# nrf54l09_enga_application register map
Vendor: Nordic Semiconductor; Series: nrf54l; File version: 1
CPU: CM33 r0p4, little endian, MPU, FPU, 3 interrupt priority bits, 270 interrupts, 4 SAU regions
Registers are 32-bit, read-write, reset 0x0 unless marked. A register's access mark holds for its fields unless they carry their own. Offsets are from the block's base; [hi:lo] are bit positions; lines under a group give offsets from that group; {n}, {i} and the like mark numbered series; 'fields as' and 'values as' point back to an identical list.

## GLOBAL_ECB00_NS — AES ECB Mode Encryption 0
Base 0x4004B000
Same registers: GLOBAL_ECB00_S 0x5004B000
0x00 TASKS_START wo — Start ECB block encrypt
  [0] TASKS_START
    1=Trigger task
0x04 TASKS_STOP wo — Abort a possible executing ECB operation
  [0] TASKS_STOP
    1=Trigger task
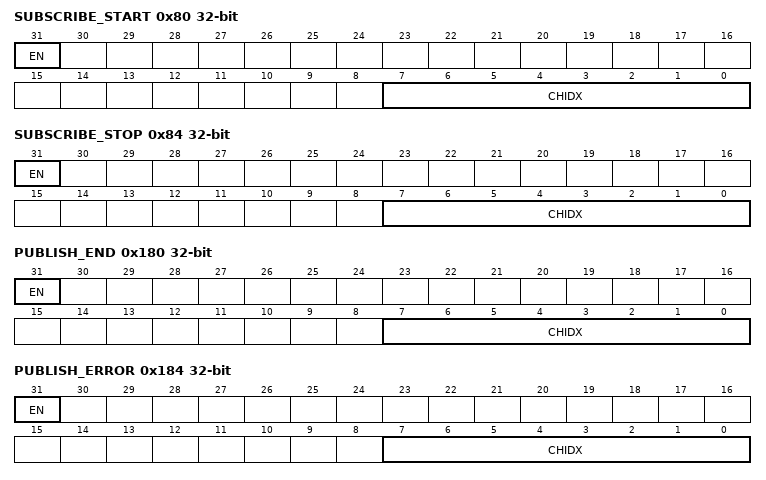
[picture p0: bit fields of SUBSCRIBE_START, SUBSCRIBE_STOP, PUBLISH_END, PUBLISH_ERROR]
0x80 SUBSCRIBE_START — Subscribe configuration for task START
  [31] EN
    0=Disabled (Disable subscription); 1=Enabled (Enable subscription)
  [7:0] CHIDX — DPPI channel that task START will subscribe to
0x84 SUBSCRIBE_STOP — Subscribe configuration for task STOP
  [31] EN
    values as SUBSCRIBE_START.EN
  [7:0] CHIDX — DPPI channel that task STOP will subscribe to
0x100 EVENTS_END — ECB block encrypt complete
  [0] EVENTS_END
    0=NotGenerated (Event not generated); 1=Generated (Event generated)
0x104 EVENTS_ERROR — ECB block encrypt aborted because of a STOP task or due to an error
  [0] EVENTS_ERROR
    values as EVENTS_END.EVENTS_END
0x180 PUBLISH_END — Publish configuration for event END
  [31] EN
    0=Disabled (Disable publishing); 1=Enabled (Enable publishing)
  [7:0] CHIDX — DPPI channel that event END will publish to
0x184 PUBLISH_ERROR — Publish configuration for event ERROR
  [31] EN
    values as PUBLISH_END.EN
  [7:0] CHIDX — DPPI channel that event ERROR will publish to
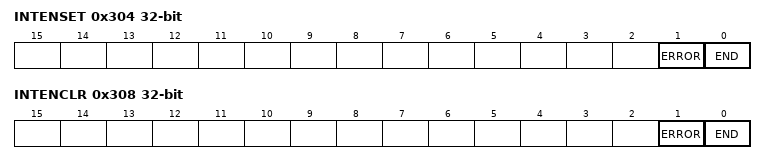
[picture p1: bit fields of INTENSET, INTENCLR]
0x304 INTENSET — Enable interrupt
  [1] ERROR — Write '1' to enable interrupt for event ERROR
    on read: 0=Disabled (Read: Disabled); 1=Enabled (Read: Enabled) | on write: 1=Set (Enable)
  [0] END — Write '1' to enable interrupt for event END
    values as ERROR
0x308 INTENCLR — Disable interrupt
  [1] ERROR — Write '1' to disable interrupt for event ERROR
    on read: 0=Disabled (Read: Disabled); 1=Enabled (Read: Enabled) | on write: 1=Clear (Disable)
  [0] END — Write '1' to disable interrupt for event END
    values as ERROR
0x400 ERRORSTATUS ro
  [2:0] ERRORSTATUS — Error status when the ERROR event is generated
    0=No errors have occurred; 1=PrematureInptrEnd (End of INPTR job list before data structure was read.); 2=PrematureOutptrEnd (End of OUTPTR job list before data structure was read.); 3=EncryptionTooSlow (Deprecated enumerator - Encryption aborted due to higher priority peripheral requesting or using the AES module.); 3=Aborted (Encryption aborted due to higher priority peripheral requesting or using the AES module.); 4=DmaError (Bus error during DMA access.)
0x510 KEY group — Unspecified
  {0x0+4j} VALUE[{j}] (j=0..3) wo — Description collection: 128-bit AES key
    [31:0] VALUE — AES 128-bit key value, bits (32*(n+1))-1 : (32*n)
0x530 IN group — IN EasyDMA channel
  0x00 PTR — Input pointer
    [31:0] PTR — Points to a job list containing unencrypted ECB data structure
0x538 OUT group — OUT EasyDMA channel
  0x00 PTR — Output pointer Points to a job list containing encrypted ECB data structure
    [31:0] PTR — Output pointer

## GLOBAL_GLITCHDET_S — Voltage glitch detectors
Base 0x5004E000
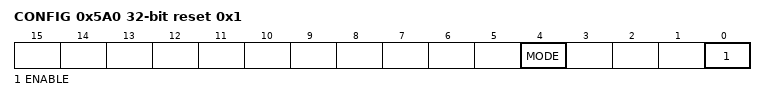
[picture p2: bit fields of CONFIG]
0x5A0 CONFIG reset 0x1 — Configuration for glitch detector
  [4] MODE — Glitch detector mode
    0=High pass filter mode; 1=Cap divider mode
  [0] ENABLE — Enable glitch detector
    0=Disable glitch detector; 1=Enable glitch detector

## GLOBAL_CTRLAP_NS — Control access port 0
Base 0x40052000
Same registers: GLOBAL_CTRLAP_S 0x50052000
0x100 EVENTS_RXREADY — RXSTATUS is changed to DataPending.
  [0] EVENTS_RXREADY
    0=NotGenerated (Event not generated); 1=Generated (Event generated)
0x104 EVENTS_TXDONE — TXSTATUS is changed to NoDataPending.
  [0] EVENTS_TXDONE
    values as EVENTS_RXREADY.EVENTS_RXREADY
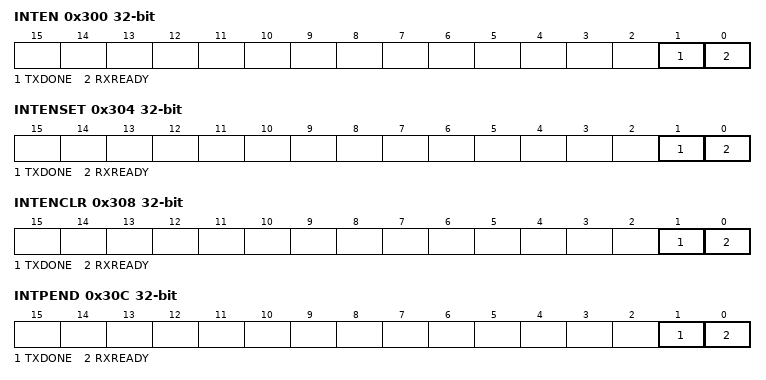
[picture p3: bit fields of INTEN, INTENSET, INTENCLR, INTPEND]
0x300 INTEN — Enable or disable interrupt
  [1] TXDONE — Enable or disable interrupt for event TXDONE
    0=Disabled; 1=Enabled
  [0] RXREADY — Enable or disable interrupt for event RXREADY
    0=Disabled; 1=Enabled
0x304 INTENSET — Enable interrupt
  [1] TXDONE — Write '1' to enable interrupt for event TXDONE
    on read: 0=Disabled (Read: Disabled); 1=Enabled (Read: Enabled) | on write: 1=Set (Enable)
  [0] RXREADY — Write '1' to enable interrupt for event RXREADY
    values as TXDONE
0x308 INTENCLR — Disable interrupt
  [1] TXDONE — Write '1' to disable interrupt for event TXDONE
    on read: 0=Disabled (Read: Disabled); 1=Enabled (Read: Enabled) | on write: 1=Clear (Disable)
  [0] RXREADY — Write '1' to disable interrupt for event RXREADY
    values as TXDONE
0x30C INTPEND ro — Pending interrupts
  [1] TXDONE — Read pending status of interrupt for event TXDONE
    on read: 0=NotPending (Read: Not pending); 1=Pending (Read: Pending)
  [0] RXREADY — Read pending status of interrupt for event RXREADY
    values as TXDONE
0x400 MAILBOX group — Unspecified
  0x00 RXDATA ro — Data sent from the debugger to the CPU.
    [31:0] RXDATA — Data received from debugger.
  0x04 RXSTATUS ro — Status to indicate if data sent from the debugger to the CPU has been read.
    [0] RXSTATUS — Status of data in register RXDATA.
      0=NoDataPending (No data is pending in register RXDATA.); 1=DataPending (Data is pending in register RXDATA.)
  0x80 TXDATA — Data sent from the CPU to the debugger.
    [31:0] TXDATA — Data sent to debugger.
  0x84 TXSTATUS ro — Status to indicate if data sent from the CPU to the debugger has been read.
    [0] TXSTATUS — Status of data in register TXDATA.
      0=NoDataPending (No data is pending in register TXDATA.); 1=DataPending (Data is pending in register TXDATA.)
0x500 ERASEPROTECT group — Unspecified
  0x00 LOCK rw-once — This register locks the ERASEPROTECT.DISABLE register from being written until next reset.
    [0] LOCK — Lock ERASEPROTECT.DISABLE register from being written until next reset.
      0=Unlocked (Register ERASEPROTECT.DISABLE is writeable.); 1=Locked (Register ERASEPROTECT.DISABLE is read-only.)
  0x04 DISABLE write-once — This register disables the ERASEPROTECT register and performs an ERASEALL operation.
    [31:0] KEY — The ERASEALL sequence is initiated if the value of the KEY fields are non-zero and the KEY fields match on both the CPU and debugger sides.
0x520 RESET wo — System reset request.
  [2:0] RESET — Reset request
    0=No reset is generated; 1=SoftReset (Perform a device soft reset); 2=HardReset (Perform a device hard reset); 4=PinReset (Perform a device pin reset)

## Notices in the file
Copyright (c) 2010 - 2025, Nordic Semiconductor ASA All rights reserved.
SPDX-License-Identifier: BSD-3-Clause
Redistribution and use in source and binary forms, with or without
modification, are permitted provided that the following conditions are met:
1. Redistributions of source code must retain the above copyright notice, this
list of conditions and the following disclaimer.
2. Redistributions in binary form must reproduce the above copyright
notice, this list of conditions and the following disclaimer in the
documentation and/or other materials provided with the distribution.
3. Neither the name of Nordic Semiconductor ASA nor the names of its
contributors may be used to endorse or promote products derived from this
software without specific prior written permission.
THIS SOFTWARE IS PROVIDED BY THE COPYRIGHT HOLDERS AND CONTRIBUTORS "AS IS"
AND ANY EXPRESS OR IMPLIED WARRANTIES, INCLUDING, BUT NOT LIMITED TO, THE
IMPLIED WARRANTIES OF MERCHANTABILITY, AND FITNESS FOR A PARTICULAR PURPOSE
ARE DISCLAIMED. IN NO EVENT SHALL NORDIC SEMICONDUCTOR ASA OR CONTRIBUTORS BE
LIABLE FOR ANY DIRECT, INDIRECT, INCIDENTAL, SPECIAL, EXEMPLARY, OR
CONSEQUENTIAL DAMAGES (INCLUDING, BUT NOT LIMITED TO, PROCUREMENT OF
SUBSTITUTE GOODS OR SERVICES; LOSS OF USE, DATA, OR PROFITS; OR BUSINESS
INTERRUPTION) HOWEVER CAUSED AND ON ANY THEORY OF LIABILITY, WHETHER IN
CONTRACT, STRICT LIABILITY, OR TORT (INCLUDING NEGLIGENCE OR OTHERWISE)
ARISING IN ANY WAY OUT OF THE USE OF THIS SOFTWARE, EVEN IF ADVISED OF THE
POSSIBILITY OF SUCH DAMAGE.
